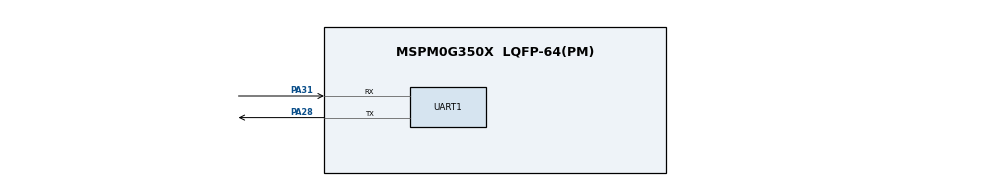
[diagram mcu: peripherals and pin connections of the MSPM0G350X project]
/**
 * @cliArgs --device "MSPM0G350X" --part "Default" --package "LQFP-64(PM)" --product "mspm0_sdk@2.10.00.04"
 * @versions {"tool":"1.26.2+4477"}
 */

/**
 * Import the modules used in this configuration.
 */
const EVENT  = scripting.addModule("/ti/driverlib/EVENT");
const SYSCTL = scripting.addModule("/ti/driverlib/SYSCTL");
const UART   = scripting.addModule("/ti/driverlib/UART", {}, false);
const UART1  = UART.addInstance();

/**
 * Write custom configuration values to the imported modules.
 */
const divider7       = system.clockTree["PLL_PDIV"];
divider7.divideValue = 2;

const divider9       = system.clockTree["UDIV"];
divider9.divideValue = 2;

const multiplier2         = system.clockTree["PLL_QDIV"];
multiplier2.multiplyValue = 8;

const mux4       = system.clockTree["EXHFMUX"];
mux4.inputSelect = "EXHFMUX_XTAL";

const mux8       = system.clockTree["HSCLKMUX"];
mux8.inputSelect = "HSCLKMUX_SYSPLL0";

const mux12       = system.clockTree["SYSPLLMUX"];
mux12.inputSelect = "zSYSPLLMUX_HFCLK";

const pinFunction4     = system.clockTree["HFXT"];
pinFunction4.inputFreq = 40;
pinFunction4.enable    = true;

const Board = scripting.addModule("/ti/driverlib/Board", {}, false);

SYSCTL.forceDefaultClkConfig = true;
SYSCTL.clockTreeEn           = true;

UART1.$name                            = "PRINT";
UART1.targetBaudRate                   = 115200;
UART1.enabledInterrupts                = ["RX"];
UART1.peripheral.rxPin.$assign         = "PA31";
UART1.peripheral.txPin.$assign         = "PA28";
UART1.txPinConfig.$name                = "ti_driverlib_gpio_GPIOPinGeneric0";
UART1.txPinConfig.direction            = scripting.forceWrite("OUTPUT");
UART1.txPinConfig.hideOutputInversion  = scripting.forceWrite(false);
UART1.txPinConfig.onlyInternalResistor = scripting.forceWrite(false);
UART1.txPinConfig.passedPeripheralType = scripting.forceWrite("Digital");
UART1.rxPinConfig.$name                = "ti_driverlib_gpio_GPIOPinGeneric1";
UART1.rxPinConfig.hideOutputInversion  = scripting.forceWrite(false);
UART1.rxPinConfig.onlyInternalResistor = scripting.forceWrite(false);
UART1.rxPinConfig.passedPeripheralType = scripting.forceWrite("Digital");

/**
 * Pinmux solution for unlocked pins/peripherals. This ensures that minor changes to the automatic solver in a future
 * version of the tool will not impact the pinmux you originally saw.  These lines can be completely deleted in order to
 * re-solve from scratch.
 */
pinFunction4.peripheral.$suggestSolution           = "SYSCTL";
pinFunction4.peripheral.hfxInPin.$suggestSolution  = "PA5";
pinFunction4.peripheral.hfxOutPin.$suggestSolution = "PA6";
Board.peripheral.$suggestSolution                  = "DEBUGSS";
Board.peripheral.swclkPin.$suggestSolution         = "PA20";
Board.peripheral.swdioPin.$suggestSolution         = "PA19";
UART1.peripheral.$suggestSolution                  = "UART0";
